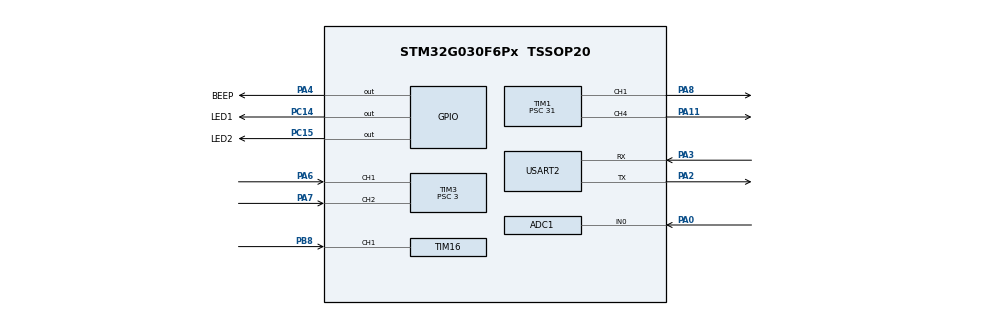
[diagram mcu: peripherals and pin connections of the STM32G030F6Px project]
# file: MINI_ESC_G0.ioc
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ADC1.Channel-0\#ChannelRegularConversion=ADC_CHANNEL_0
ADC1.ContinuousConvMode=ENABLE
ADC1.DMAContinuousRequests=ENABLE
ADC1.NbrOfConversionFlag=1
ADC1.Rank-0\#ChannelRegularConversion=1
ADC1.SamplingTime-0\#ChannelRegularConversion=ADC_SAMPLINGTIME_COMMON_1
ADC1.SamplingTimeCommon1=ADC_SAMPLETIME_12CYCLES_5
ADC1.SamplingTimeCommon2=ADC_SAMPLETIME_7CYCLES_5
ADC1.SelectedChannel=ADC_CHANNEL_0
ADC1.master=1
Dma.ADC1.0.Direction=DMA_PERIPH_TO_MEMORY
Dma.ADC1.0.EventEnable=DISABLE
Dma.ADC1.0.Instance=DMA1_Channel1
Dma.ADC1.0.MemDataAlignment=DMA_MDATAALIGN_HALFWORD
Dma.ADC1.0.MemInc=DMA_MINC_DISABLE
Dma.ADC1.0.Mode=DMA_CIRCULAR
Dma.ADC1.0.PeriphDataAlignment=DMA_PDATAALIGN_HALFWORD
Dma.ADC1.0.PeriphInc=DMA_PINC_DISABLE
Dma.ADC1.0.Polarity=HAL_DMAMUX_REQ_GEN_RISING
Dma.ADC1.0.Priority=DMA_PRIORITY_HIGH
Dma.ADC1.0.RequestNumber=1
Dma.ADC1.0.SignalID=NONE
Dma.ADC1.0.SyncEnable=DISABLE
Dma.ADC1.0.SyncPolarity=HAL_DMAMUX_SYNC_NO_EVENT
Dma.ADC1.0.SyncRequestNumber=1
Dma.ADC1.0.SyncSignalID=NONE
Dma.Request0=ADC1
Mcu.Family=STM32G0
Mcu.Name=STM32G030F6Px
Mcu.Package=TSSOP20
NVIC.DMA1_Channel1_IRQn=true\:0\:0\:false\:false\:true\:false\:true\:true
NVIC.TIM14_IRQn=true\:0\:0\:false\:false\:true\:true\:true\:true
NVIC.TIM16_IRQn=true\:1\:0\:true\:false\:true\:true\:true\:true
NVIC.TIM17_IRQn=true\:0\:0\:false\:false\:true\:true\:true\:true
PA0.Mode=IN0
PA0.Signal=ADC1_IN0
PA11\ [PA9].Signal=S_TIM1_CH4
PA13.Mode=Serial_Wire
PA13.Signal=SYS_SWDIO
PA14-BOOT0.Mode=Serial_Wire
PA14-BOOT0.Signal=SYS_SWCLK
PA14-BOOT0__PA15.StandardMode=true
PA2.Mode=Asynchronous
PA2.Signal=USART2_TX
PA3.Mode=Asynchronous
PA3.Signal=USART2_RX
PA4.GPIO_Label=BEEP
PA4.Signal=GPIO_Output
PA6.Signal=S_TIM3_CH1
PA7.Signal=S_TIM3_CH2
PA8.Signal=S_TIM1_CH1
PB0__PB1__PB2__PA8.StandardMode=true
PB3__PB4__PB5__PB6.StandardMode=true
PB7__PB8.StandardMode=true
PB8.Signal=S_TIM16_CH1
PC14-OSC32_IN\ (PC14).GPIO_Label=LED1
PC14-OSC32_IN\ (PC14).Signal=GPIO_Output
PC14-OSC32_IN\ (PC14)__PB9.StandardMode=true
PC15-OSC32_OUT\ (PC15).GPIO_Label=LED2
PC15-OSC32_OUT\ (PC15).Signal=GPIO_Output
ProjectManager.HeapSize=0x200
ProjectManager.StackSize=0x400
ProjectManager.TargetToolchain=MDK-ARM V5.32
RCC.ADCFreq_Value=64000000
RCC.AHBFreq_Value=64000000
RCC.CortexFreq_Value=64000000
RCC.EXTERNAL_CLOCK_VALUE=12288000
RCC.HCLKFreq_Value=64000000
RCC.HSE_VALUE=8000000
RCC.HSI_VALUE=16000000
RCC.LSE_VALUE=32768
RCC.SYSCLKFreq_VALUE=64000000
RCC.SYSCLKSource=RCC_SYSCLKSOURCE_PLLCLK
RCC.VCOOutputFreq_Value=128000000
SH.S_TIM16_CH1.0=TIM16_CH1,Input_Capture1_from_TI1
SH.S_TIM1_CH1.0=TIM1_CH1,PWM Generation1 CH1
SH.S_TIM1_CH4.0=TIM1_CH4,PWM Generation4 CH4
SH.S_TIM3_CH1.0=TIM3_CH1,Encoder_Interface
SH.S_TIM3_CH2.0=TIM3_CH2,Encoder_Interface
TIM1.Channel-PWM\ Generation1\ CH1=TIM_CHANNEL_1
TIM1.Channel-PWM\ Generation4\ CH4=TIM_CHANNEL_4
TIM1.Period=999
TIM1.Prescaler=31
TIM14.Period=1999
TIM14.Prescaler=639
TIM16.Channel=TIM_CHANNEL_1
TIM16.Period=999
TIM16.Prescaler=6399
TIM17.Period=999
TIM17.Prescaler=639
TIM3.EncoderMode=TIM_ENCODERMODE_TI12
TIM3.IC1Filter=15
TIM3.IC2Filter=15
TIM3.Prescaler=3
USART2.VirtualMode-Asynchronous=VM_ASYNC
VP_TIM14_VS_ClockSourceINT.Mode=Enable_Timer
VP_TIM16_VS_ClockSourceINT.Mode=Enable_Timer
VP_TIM17_VS_ClockSourceINT.Mode=Enable_Timer
board=custom

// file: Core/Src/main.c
/* USER CODE BEGIN Header */
/**
  ******************************************************************************
  * @file           : main.c
  * @brief          : Main program body
  ******************************************************************************
  * @attention
  *
  * Copyright (c) 2022 STMicroelectronics.
  * All rights reserved.
  *
  * This software is licensed under terms that can be found in the LICENSE file
  * in the root directory of this software component.
  * If no LICENSE file comes with this software, it is provided AS-IS.
  *
  ******************************************************************************
  */
/* USER CODE END Header */
#include "main.h"
#include "adc.h"
#include "dma.h"
#include "tim.h"
#include "usart.h"
#include "gpio.h"

/* USER CODE BEGIN Includes */
#include "control.h"
/* USER CODE END Includes */

/* USER CODE BEGIN PV */
short speed = 0;
extern ESC_Para MyESC;
/* USER CODE END PV */

void SystemClock_Config(void);

int main(void)
{

  /* MCU Configuration--------------------------------------------------------*/

  /* Reset of all peripherals, Initializes the Flash interface and the Systick. */
  HAL_Init();

  /* Configure the system clock */
  SystemClock_Config();

  /* USER CODE BEGIN SysInit */
	/*****************************�ǵõ���DMA��ADC_Init��˳�� ��DMA��ADC *********************************/
  /* USER CODE END SysInit */

  /* Initialize all configured peripherals */
  MX_GPIO_Init();
	MX_DMA_Init();
  MX_ADC1_Init();
  MX_TIM1_Init();
  MX_TIM14_Init();
  MX_TIM16_Init();
  MX_TIM3_Init();
  MX_USART2_UART_Init();
  MX_TIM17_Init();
  /* USER CODE BEGIN 2 */
	PID_init();
	LL_GPIO_SetOutputPin(GPIOC,GPIO_PIN_14);
	LL_mDelay(500);
	LL_GPIO_ResetOutputPin(GPIOC,GPIO_PIN_14);
	LL_mDelay(5);
  /* USER CODE END 2 */

  /* Infinite loop */
  while (1)
  {

    /* USER CODE BEGIN 3 */
		Mean_Filter();
		PWM_TO_SPEED();

  }
  /* USER CODE END 3 */
}

void SystemClock_Config(void)
{
  LL_FLASH_SetLatency(LL_FLASH_LATENCY_2);
  while(LL_FLASH_GetLatency() != LL_FLASH_LATENCY_2)
  {
  }

  /* HSI configuration and activation */
  LL_RCC_HSI_Enable();
  while(LL_RCC_HSI_IsReady() != 1)
  {
  }

  /* Main PLL configuration and activation */
  LL_RCC_PLL_ConfigDomain_SYS(LL_RCC_PLLSOURCE_HSI, LL_RCC_PLLM_DIV_1, 8, LL_RCC_PLLR_DIV_2);
  LL_RCC_PLL_Enable();
  LL_RCC_PLL_EnableDomain_SYS();
  while(LL_RCC_PLL_IsReady() != 1)
  {
  }

  /* Set AHB prescaler*/
  LL_RCC_SetAHBPrescaler(LL_RCC_SYSCLK_DIV_1);

  /* Sysclk activation on the main PLL */
  LL_RCC_SetSysClkSource(LL_RCC_SYS_CLKSOURCE_PLL);
  while(LL_RCC_GetSysClkSource() != LL_RCC_SYS_CLKSOURCE_STATUS_PLL)
  {
  }

  /* Set APB1 prescaler*/
  LL_RCC_SetAPB1Prescaler(LL_RCC_APB1_DIV_1);
  /* Update CMSIS variable (which can be updated also through SystemCoreClockUpdate function) */
  LL_SetSystemCoreClock(64000000);

   /* Update the time base */
  if (HAL_InitTick (TICK_INT_PRIORITY) != HAL_OK)
  {
    Error_Handler();
  }
}

void Error_Handler(void)
{
  __disable_irq();
  while (1)
  {
  }
}
